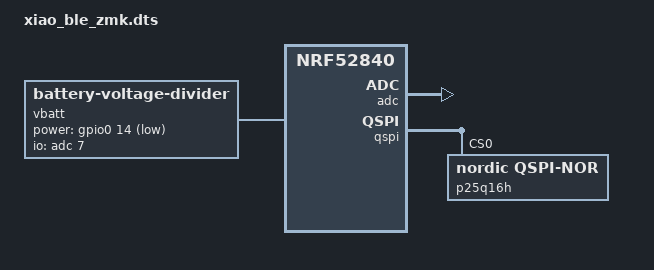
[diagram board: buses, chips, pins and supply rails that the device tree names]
/*
 * Copied verbatim below this header from zmkfirmware/zmk (MIT) for foundry/check_zmk_config.py:
 *   https://github.com/zmkfirmware/zmk/blob/9ebbeff0a8b69a42f14aec022cdf16c7a107b9e0/app/boards/seeed/xiao_ble/xiao_ble_zmk.dts
 *   (main at commit 9ebbeff0a8b6, fetched 2026-09-26. config/west.yml follows ZMK main: re-fetch when ZMK moves.)
 * The check reads which XIAO peripherals the board itself disables (e.g. &xiao_serial).
 */
/*
 * Copyright (c) 2021 The ZMK Contributors
 *
 * SPDX-License-Identifier: MIT
 */

#include <../boards/seeed/xiao_ble/xiao_ble.dts>
#include <common/nordic/nrf52840_uf2_boot_mode.dtsi>

/* Add an sd_partition label for compatibility with the nosd snippet */
sd_partition: &reserved_partition_0 { };

/ {
    chosen {
        zmk,battery = &vbatt;
    };

    vbatt: vbatt {
        compatible = "zmk,battery-voltage-divider";
        io-channels = <&adc 7>;
        power-gpios = <&gpio0 14 (GPIO_OPEN_DRAIN | GPIO_ACTIVE_LOW)>;
        output-ohms = <510000>;
        full-ohms = <(1000000 + 510000)>;
    };
};

&xiao_serial { status = "disabled"; };

&adc {
    status = "okay";
};

&qspi {
    status = "okay";
    pinctrl-0 = <&qspi_default>;
    pinctrl-1 = <&qspi_sleep>;
    pinctrl-names = "default", "sleep";
    p25q16h: p25q16h@0 {
        compatible = "nordic,qspi-nor";
        reg = <0>;
        sck-frequency = <104000000>;
        quad-enable-requirements = "S2B1v1";
        jedec-id = [85 60 15];
        sfdp-bfp = [
            e5 20 f1 ff  ff ff ff 00  44 eb 08 6b  08 3b 80 bb
            ee ff ff ff  ff ff 00 ff  ff ff 00 ff  0c 20 0f 52
            10 d8 08 81
        ];
        size = <16777216>;
        has-dpd;
        t-enter-dpd = <3000>;
        t-exit-dpd = <8000>;
    };
};
